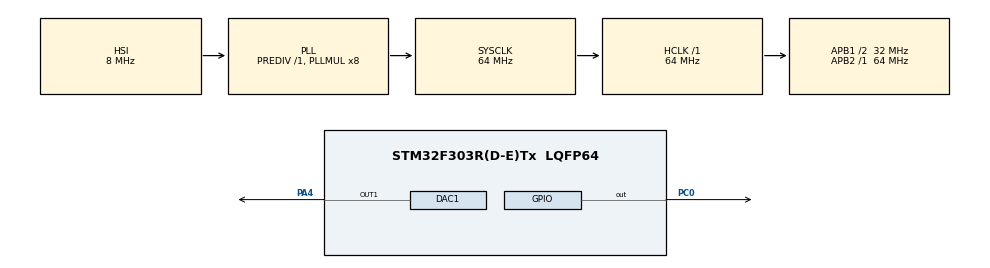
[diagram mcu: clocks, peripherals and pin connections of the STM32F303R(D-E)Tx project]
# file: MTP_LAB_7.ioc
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DAC1.DAC_Trigger=DAC_TRIGGER_T6_TRGO
Dma.DAC1_CH1.0.Direction=DMA_MEMORY_TO_PERIPH
Dma.DAC1_CH1.0.Instance=DMA1_Channel3
Dma.DAC1_CH1.0.MemDataAlignment=DMA_MDATAALIGN_BYTE
Dma.DAC1_CH1.0.MemInc=DMA_MINC_ENABLE
Dma.DAC1_CH1.0.Mode=DMA_CIRCULAR
Dma.DAC1_CH1.0.PeriphDataAlignment=DMA_PDATAALIGN_BYTE
Dma.DAC1_CH1.0.PeriphInc=DMA_PINC_DISABLE
Dma.DAC1_CH1.0.Priority=DMA_PRIORITY_LOW
Dma.Request0=DAC1_CH1
Mcu.Family=STM32F3
Mcu.Name=STM32F303R(D-E)Tx
Mcu.Package=LQFP64
NVIC.DMA1_Channel3_IRQn=true\:0\:0\:false\:false\:true\:false\:true
NVIC.PriorityGroup=NVIC_PRIORITYGROUP_4
NVIC.TIM6_DAC_IRQn=true\:4\:0\:true\:false\:true\:true\:true
PA13.Mode=Serial_Wire
PA13.Signal=SYS_JTMS-SWDIO
PA14.Mode=Serial_Wire
PA14.Signal=SYS_JTCK-SWCLK
PA4.Signal=COMP_DAC11_group
PC0.Signal=GPIO_Output
ProjectManager.HeapSize=0x200
ProjectManager.StackSize=0x400
ProjectManager.TargetToolchain=STM32CubeIDE
RCC.AHBFreq_Value=64000000
RCC.APB1CLKDivider=RCC_HCLK_DIV2
RCC.APB1Freq_Value=32000000
RCC.APB1TimFreq_Value=64000000
RCC.APB2Freq_Value=64000000
RCC.APB2TimFreq_Value=64000000
RCC.CortexFreq_Value=64000000
RCC.HCLKFreq_Value=64000000
RCC.HSE_VALUE=8000000
RCC.HSI_VALUE=8000000
RCC.LSE_VALUE=32768
RCC.PLLMUL=RCC_PLL_MUL8
RCC.SYSCLKFreq_VALUE=64000000
RCC.SYSCLKSourceVirtual=RCC_SYSCLKSOURCE_PLLCLK
RCC.USBFreq_Value=64000000
SH.COMP_DAC11_group.0=DAC1_OUT1,DAC_OUT1
TIM6.Period=29
TIM6.Prescaler=0
TIM6.TIM_MasterOutputTrigger=TIM_TRGO_UPDATE
VP_TIM6_VS_ClockSourceINT.Mode=Enable_Timer
board=custom

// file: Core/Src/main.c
/* USER CODE BEGIN Header */
/**
  ******************************************************************************
  * @file           : main.c
  * @brief          : Main program body
  ******************************************************************************
  * @attention
  *
  * <h2><center>&copy; Copyright (c) 2021 STMicroelectronics.
  * All rights reserved.</center></h2>
  *
  * This software component is licensed by ST under BSD 3-Clause license,
  * the "License"; You may not use this file except in compliance with the
  * License. You may obtain a copy of the License at:
  *                        opensource.org/licenses/BSD-3-Clause
  *
  ******************************************************************************
  */
/* USER CODE END Header */

#include "main.h"

/* USER CODE BEGIN Includes */
#include <math.h>
/* USER CODE END Includes */

/* USER CODE BEGIN PV */
#define RESOLUTION	256.0

uint8_t ubSinValues[(int)RESOLUTION];
uint8_t sindex;
/* USER CODE END PV */

void SystemClock_Config(void);
static void MX_GPIO_Init(void);
static void MX_DMA_Init(void);
static void MX_DAC1_Init(void);
static void MX_TIM6_Init(void);

int main(void)
{
  /* USER CODE BEGIN 1 */

  for (uint16_t i = 0; i < (int)RESOLUTION; i++) {
	  ubSinValues[i] = (uint8_t)((sin((double)M_PI*2.0*(double)i/RESOLUTION) * (double)0.5 + (double)0.7)*(double)(RESOLUTION-50));
  }

  /* USER CODE END 1 */

  /* MCU Configuration--------------------------------------------------------*/

  /* Reset of all peripherals, Initializes the Flash interface and the Systick. */
  HAL_Init();

  /* Configure the system clock */
  SystemClock_Config();

  /* Initialize all configured peripherals */
  MX_GPIO_Init();
  MX_DMA_Init();
  MX_DAC1_Init();
  MX_TIM6_Init();
  /* USER CODE BEGIN 2 */

  LL_DMA_SetMemoryAddress(DMA1, LL_DMA_CHANNEL_3, (uint32_t)ubSinValues);
  LL_DMA_SetDataLength(DMA1, LL_DMA_CHANNEL_3, RESOLUTION);
  LL_DMA_SetPeriphAddress(DMA1, LL_DMA_CHANNEL_3, (uint32_t)&DAC1->DHR8R1);
  LL_DMA_EnableChannel(DMA1, LL_DMA_CHANNEL_3);

  LL_DAC_EnableDMAReq(DAC1, LL_DAC_CHANNEL_1);

  LL_TIM_ClearFlag_UPDATE(TIM6);
  LL_TIM_EnableCounter(TIM6);

  LL_DAC_Enable(DAC1, LL_DAC_CHANNEL_1);

  /* USER CODE END 2 */

  /* Infinite loop */
  while (1)
  {

  }
}

void SystemClock_Config(void)
{
  RCC_OscInitTypeDef RCC_OscInitStruct = {0};
  RCC_ClkInitTypeDef RCC_ClkInitStruct = {0};

  /** Initializes the CPU, AHB and APB busses clocks
  */
  RCC_OscInitStruct.OscillatorType = RCC_OSCILLATORTYPE_HSI;
  RCC_OscInitStruct.HSIState = RCC_HSI_ON;
  RCC_OscInitStruct.HSICalibrationValue = RCC_HSICALIBRATION_DEFAULT;
  RCC_OscInitStruct.PLL.PLLState = RCC_PLL_ON;
  RCC_OscInitStruct.PLL.PLLSource = RCC_PLLSOURCE_HSI;
  RCC_OscInitStruct.PLL.PLLMUL = RCC_PLL_MUL8;
  RCC_OscInitStruct.PLL.PREDIV = RCC_PREDIV_DIV1;
  if (HAL_RCC_OscConfig(&RCC_OscInitStruct) != HAL_OK)
  {
    Error_Handler();
  }
  /** Initializes the CPU, AHB and APB busses clocks
  */
  RCC_ClkInitStruct.ClockType = RCC_CLOCKTYPE_HCLK|RCC_CLOCKTYPE_SYSCLK
                              |RCC_CLOCKTYPE_PCLK1|RCC_CLOCKTYPE_PCLK2;
  RCC_ClkInitStruct.SYSCLKSource = RCC_SYSCLKSOURCE_PLLCLK;
  RCC_ClkInitStruct.AHBCLKDivider = RCC_SYSCLK_DIV1;
  RCC_ClkInitStruct.APB1CLKDivider = RCC_HCLK_DIV2;
  RCC_ClkInitStruct.APB2CLKDivider = RCC_HCLK_DIV1;

  if (HAL_RCC_ClockConfig(&RCC_ClkInitStruct, FLASH_LATENCY_2) != HAL_OK)
  {
    Error_Handler();
  }
}

static void MX_DAC1_Init(void)
{

  LL_DAC_InitTypeDef DAC_InitStruct = {0};

  LL_GPIO_InitTypeDef GPIO_InitStruct = {0};

  /* Peripheral clock enable */
  LL_APB1_GRP1_EnableClock(LL_APB1_GRP1_PERIPH_DAC1);

  LL_AHB1_GRP1_EnableClock(LL_AHB1_GRP1_PERIPH_GPIOA);
  /**DAC1 GPIO Configuration
  PA4   ------> DAC1_OUT1
  */
  GPIO_InitStruct.Pin = LL_GPIO_PIN_4;
  GPIO_InitStruct.Mode = LL_GPIO_MODE_ANALOG;
  GPIO_InitStruct.Pull = LL_GPIO_PULL_NO;
  LL_GPIO_Init(GPIOA, &GPIO_InitStruct);

  /* DAC1 DMA Init */

  /* DAC1_CH1 Init */
  LL_DMA_SetDataTransferDirection(DMA1, LL_DMA_CHANNEL_3, LL_DMA_DIRECTION_MEMORY_TO_PERIPH);

  LL_DMA_SetChannelPriorityLevel(DMA1, LL_DMA_CHANNEL_3, LL_DMA_PRIORITY_VERYHIGH);

  LL_DMA_SetMode(DMA1, LL_DMA_CHANNEL_3, LL_DMA_MODE_CIRCULAR);

  LL_DMA_SetPeriphIncMode(DMA1, LL_DMA_CHANNEL_3, LL_DMA_PERIPH_NOINCREMENT);

  LL_DMA_SetMemoryIncMode(DMA1, LL_DMA_CHANNEL_3, LL_DMA_MEMORY_INCREMENT);

  LL_DMA_SetPeriphSize(DMA1, LL_DMA_CHANNEL_3, LL_DMA_PDATAALIGN_BYTE);

  LL_DMA_SetMemorySize(DMA1, LL_DMA_CHANNEL_3, LL_DMA_MDATAALIGN_BYTE);

  LL_SYSCFG_SetRemapDMA_DAC(LL_SYSCFG_DAC1_CH1_RMP_DMA1_CH3);

  /* DAC1 interrupt Init */
  NVIC_SetPriority(TIM6_DAC_IRQn, NVIC_EncodePriority(NVIC_GetPriorityGrouping(),4, 0));
  NVIC_EnableIRQ(TIM6_DAC_IRQn);

  /** DAC channel OUT1 config
  */
  DAC_InitStruct.TriggerSource = LL_DAC_TRIG_EXT_TIM6_TRGO;
  DAC_InitStruct.WaveAutoGeneration = LL_DAC_WAVE_AUTO_GENERATION_NONE;
  DAC_InitStruct.OutputBuffer = LL_DAC_OUTPUT_BUFFER_ENABLE;
  LL_DAC_Init(DAC1, LL_DAC_CHANNEL_1, &DAC_InitStruct);
  LL_DAC_EnableTrigger(DAC1, LL_DAC_CHANNEL_1);

}

static void MX_TIM6_Init(void)
{

  LL_TIM_InitTypeDef TIM_InitStruct = {0};

  /* Peripheral clock enable */
  LL_APB1_GRP1_EnableClock(LL_APB1_GRP1_PERIPH_TIM6);

  /* TIM6 interrupt Init */
  NVIC_SetPriority(TIM6_DAC_IRQn, NVIC_EncodePriority(NVIC_GetPriorityGrouping(),4, 0));
  NVIC_EnableIRQ(TIM6_DAC_IRQn);

  TIM_InitStruct.Prescaler = 0;
  TIM_InitStruct.CounterMode = LL_TIM_COUNTERMODE_UP;
  TIM_InitStruct.Autoreload = 29;
  LL_TIM_Init(TIM6, &TIM_InitStruct);
  LL_TIM_DisableARRPreload(TIM6);
  LL_TIM_SetTriggerOutput(TIM6, LL_TIM_TRGO_UPDATE);
  LL_TIM_DisableMasterSlaveMode(TIM6);

}

static void MX_DMA_Init(void)
{

  /* Init with LL driver */
  /* DMA controller clock enable */
  LL_AHB1_GRP1_EnableClock(LL_AHB1_GRP1_PERIPH_DMA1);

  /* DMA interrupt init */
  /* DMA1_Channel3_IRQn interrupt configuration */
  NVIC_SetPriority(DMA1_Channel3_IRQn, NVIC_EncodePriority(NVIC_GetPriorityGrouping(),0, 0));
  NVIC_EnableIRQ(DMA1_Channel3_IRQn);

}

static void MX_GPIO_Init(void)
{
  GPIO_InitTypeDef GPIO_InitStruct = {0};

  /* GPIO Ports Clock Enable */
  __HAL_RCC_GPIOC_CLK_ENABLE();
  __HAL_RCC_GPIOA_CLK_ENABLE();

  /*Configure GPIO pin Output Level */
  HAL_GPIO_WritePin(GPIOC, GPIO_PIN_0, GPIO_PIN_RESET);

  /*Configure GPIO pin : PC0 */
  GPIO_InitStruct.Pin = GPIO_PIN_0;
  GPIO_InitStruct.Mode = GPIO_MODE_OUTPUT_PP;
  GPIO_InitStruct.Pull = GPIO_NOPULL;
  GPIO_InitStruct.Speed = GPIO_SPEED_FREQ_LOW;
  HAL_GPIO_Init(GPIOC, &GPIO_InitStruct);

}

void Error_Handler(void)
{
}

/************************ (C) COPYRIGHT STMicroelectronics *****END OF FILE****/
